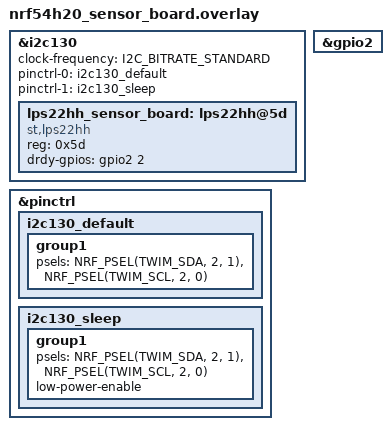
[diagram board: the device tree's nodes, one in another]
/* Copyright (c) 2024 Nordic Semiconductor ASA
 *
 * SPDX-License-Identifier: LicenseRef-Nordic-5-Clause
 */

&i2c130 {
	status = "okay";
	clock-frequency = <I2C_BITRATE_STANDARD>;
	pinctrl-0 = <&i2c130_default>;
	pinctrl-1 = <&i2c130_sleep>;
	pinctrl-names = "default", "sleep";
	
	lps22hh_sensor_board: lps22hh@5d {
		compatible = "st,lps22hh";
		status = "okay";
		reg = <0x5d>;
		drdy-gpios =  <&gpio2 2 GPIO_ACTIVE_HIGH>;
	};
};

&gpio2 {
	status = "okay";
};

&pinctrl {
	i2c130_default: i2c130_default {
		group1 {
			psels = <NRF_PSEL(TWIM_SDA, 2, 1)>,
				<NRF_PSEL(TWIM_SCL, 2, 0)>;
		};
	};

	i2c130_sleep: i2c130_sleep {
		group1 {
			psels = <NRF_PSEL(TWIM_SDA, 2, 1)>,
				<NRF_PSEL(TWIM_SCL, 2, 0)>;
			low-power-enable;
		};
	};
};
